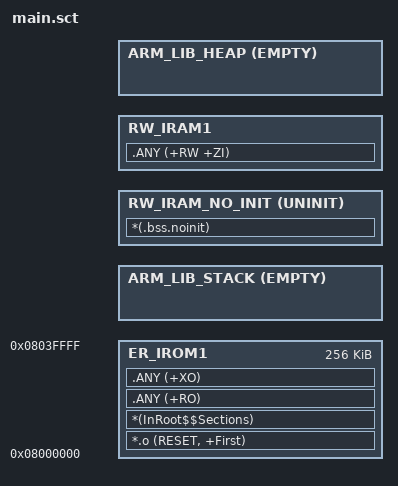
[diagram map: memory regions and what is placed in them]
#! armclang --target=arm-arm-none-eabi -mcpu=cortex-m0 -E -xc

#include "..\cfg.h"



LR_IROM1 0x08000000 0x00040000  {    
  ER_IROM1 0x08000000 0x00040000  {  
   *.o (RESET, +First)
   *(InRoot$$Sections)
   .ANY (+RO)
   .ANY (+XO)
  }   
  ARM_LIB_STACK RAM1_BASE ALIGN 8 FILL 0xDEADBEEF EMPTY STACK_SIZE {}  
      
  RW_IRAM_NO_INIT +0 UNINIT{
    *(.bss.noinit)
  }   
      
  RW_IRAM1 +0 { 
   .ANY (+RW +ZI)
  }
 
  ARM_LIB_HEAP +0 ALIGN 8 EMPTY HEAP_SIZE {}
  ScatterAssert(ImageLimit(ARM_LIB_HEAP) <= RAM1_LIMIT)
}
